# M55M1 register map
File version: 1.0
Registers are 32-bit, read-write, reset 0x0 unless marked. A register's access mark holds for its fields unless they carry their own. Offsets are from the block's base; [hi:lo] are bit positions; {n}, {i} and the like mark numbered series; 'fields as' and 'values as' point back to an identical list.

## SCU_NS — SCU Register Map
Base 0x50402000
0x60 SCU_FNSADDR ro reset not defined — Flash Non-secure Boundary Address Register
  [31:0] FNSADDR — Flash Non-secure Boundary Address. Indicate the base address of Non-secure region set in user configuration. Refer to FMC section for more details.
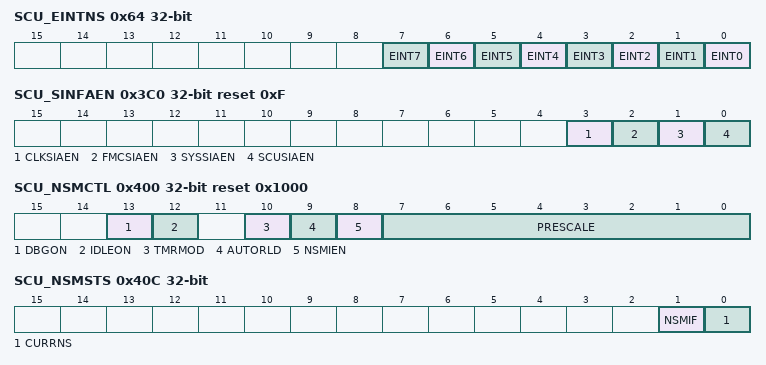
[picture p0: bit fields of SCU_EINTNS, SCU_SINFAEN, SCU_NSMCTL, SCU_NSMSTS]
0x64 SCU_EINTNS — EINT Non-secure Attribution Set Register
  [n] EINT{n} (n=0..7) — Set EINT{n} to Non-secure State
    0=EINT{n} is a secure module (default); 1=EINT{n} is a non-secure module
0x70 SCU_IONS0 — I/O Non-secure Attribution Set Register0
  [15:0] PA — Set GPIO Port A to Non-secure State. Write 1 to set PA to non-secure state. Each bit configures one pin in GPIO port A.
    0=GPIO port A is secure (default); 1=GPIO port A is non-secure
0x74 SCU_IONS1 — I/O Non-secure Attribution Set Register1
  [15:0] PB — Set GPIO Port B to Non-secure State. Write 1 to set PB to non-secure state. Each bit configures one pin in GPIO port B.
    0=GPIO port B is secure (default); 1=GPIO port B is non-secure
0x78 SCU_IONS2 — I/O Non-secure Attribution Set Register2
  [15:0] PC — Set GPIO Port C to Non-secure State. Write 1 to set PC to non-secure state. Each bit configures one pin in GPIO port C.
    0=GPIO port C is secure (default); 1=GPIO port C is non-secure
0x7C SCU_IONS3 — I/O Non-secure Attribution Set Register3
  [15:0] PD — Set GPIO Port D to Non-secure State. Write 1 to set PD to non-secure state. Each bit configures one pin in GPIO port D.
    0=GPIO port D is secure (default); 1=GPIO port D is non-secure
0x80 SCU_IONS4 — I/O Non-secure Attribution Set Register4
  [15:0] PE — Set GPIO Port E to Non-secure State. Write 1 to set PE to non-secure state. Each bit configures one pin in GPIO port E.
    0=GPIO port E is secure (default); 1=GPIO port E is non-secure
0x84 SCU_IONS5 — I/O Non-secure Attribution Set Register5
  [15:0] PF — Set GPIO Port F to Non-secure State. Write 1 to set PF to non-secure state. Each bit configures one pin in GPIO port F.
    0=GPIO port F is secure (default); 1=GPIO port F is non-secure
0x88 SCU_IONS6 — I/O Non-secure Attribution Set Register6
  [15:0] PG — Set GPIO Port G to Non-secure State. Write 1 to set PG to non-secure state. Each bit configures one pin in GPIO port G.
    0=GPIO port G is secure (default); 1=GPIO port G is non-secure
0x8C SCU_IONS7 — I/O Non-secure Attribution Set Register7
  [15:0] PH — Set GPIO Port H to Non-secure State. Write 1 to set PH to non-secure state. Each bit configures one pin in GPIO port H.
    0=GPIO port H is secure (default); 1=GPIO port H is non-secure
0x90 SCU_IONS8 — I/O Non-secure Attribution Set Register8
  [15:0] PI — Set GPIO Port I to Non-secure State. Write 1 to set PI to non-secure state. Each bit configures one pin in GPIO port I.
    0=GPIO port I is secure (default); 1=GPIO port I is non-secure
0x94 SCU_IONS9 — I/O Non-secure Attribution Set Register9
  [15:0] PJ — Set GPIO Port J to Non-secure State. Write 1 to set PJ to non-secure state. Each bit configures one pin in GPIO port J.
    0=GPIO port J is secure (default); 1=GPIO port J is non-secure
0x3C0 SCU_SINFAEN reset 0xF — Shared Information Access Enable Register
  [3] CLKSIAEN — CLKCTL Shared Information Access Enable Bit
    0=Non-secure CPU access CLKCTL Shared information Disabled; 1=Non-secure CPU access CLKCTL Shared information Enabled
  [2] FMCSIAEN — FMC Shared Information Access Enable Bit
    0=Non-secure CPU access FMC Shared information Disabled; 1=Non-secure CPU access FMC Shared information Enabled
  [1] SYSSIAEN — SYS Shared Information Access Enable Bit
    0=Non-secure CPU access SYS Shared information Disabled; 1=Non-secure CPU access SYS Shared information Enabled
  [0] SCUSIAEN — SCU Shared Information Access Enable Bit
    0=Non-secure CPU access SCU Shared information Disabled; 1=Non-secure CPU access SCU Shared information Enabled
0x400 SCU_NSMCTL reset 0x1000 — Non-secure State Monitor Control Register
  [13] DBGON — Monitor Counter Keep Counting When the Chip Is in Debug Mode Enable Bit
    0=The counter will be halted when the core processor is halted by ICE. (default); 1=The counter will keep counting when the core processor is halted by ICE
  [12] IDLEON — Monitor Counter Keep Counting When the Chip Is in Idle Mode Enable Bit. Note: In monitor mode, the counter is always halted when the core processor is in secure state.
    0=The counter will be halted when the chip is in idle mode; 1=The counter will keep counting when the chip is in idle mode. (default)
  [10] TMRMOD — Non-secure Monitor Mode Enable Bit
    0=Monitor mode. The counter will count down when the core processor is in non-secure state. (default); 1=Free-counting mode. The counter will keep counting no matter the core processor is in secure or non-secure state
  [9] AUTORLD — Auto Reload Non-secure State Monitor Counter When CURRNS Changing to 1
    0=Disable clearing non-secure state monitor counter automatically (default); 1=Enable clearing non-secure state monitor counter automatically when the core processor changes from secure state to non-secure state
  [8] NSMIEN — Non-secure State Monitor Interrupt Enable Bit
    0=Non-secure state monitor interrupt Disabled; 1=Non-secure state monitor interrupt Enabled
  [7:0] PRESCALE — Pre-scale Value of Non-secure State Monitor Counter
    0=Counter Disabled
0x404 SCU_NSMLOAD reset 0xFFFFFF — Non-secure State Monitor Reload Value Register
  [23:0] RELOAD — Reload Value for Non-secure State Monitor Counter. The RELOAD value will be reloaded to the counter whenever the counter counts down to 0.
0x408 SCU_NSMVAL reset 0xFFFFFF — Non-secure State Monitor Counter Value Register
  [23:0] VALUE — Counter Value of Non-secure State Monitor Counter. A write of any value clears the VALUE to 0 and also clears NSMIF.
0x40C SCU_NSMSTS — Non-secure State Monitor Status Register
  [1] NSMIF — Non-secure State Monitor Interrupt Flag. Note: This bit is cleared by writing 1.
    0=Counter does not count down to 0 since the last NSMIF has been cleared; 1=Counter counts down to 0
  [0] CURRNS ro — Current Core Processor Secure/Non-secure State (Read Only). Note: This bit can be used to monitor the current secure/non-secure state of the core processor, even if the non-secure state monitor counter is disabled.
    0=Core processor is in secure state; 1=Core processor is in non-secure state
{0x410+4i} SCU_SRAM{i}MPCLUT0 ro (i=0..2) — Security Attribute of memory blocks controlled by SRAM{i}MPC LUT0
  [31:0] BLKLUT — Block-based gating Look Up Table. Each bit indicates the Security state of a single block. When:
    0=The corresponding block is in the Secure state; 1=The corresponding block is in the Non-secure state
0x420 SCU_SRAM3MPCLUT0 ro — Security Attribute of memory blocks controlled by SRAM3MPC LUT0
  fields as SCU_SRAM0MPCLUT0
0x424 SCU_LPSRAMMPCLUT0 ro — Security Attribute of memory blocks controlled by LPSRAMMPC LUT0
  fields as SCU_SRAM0MPCLUT0
{0x430+4i} SCU_SPIM0MPCLUT{i} ro (i=0..7) — Security Attribute of memory blocks controlled by SPIM0MPC LUT{i}
  fields as SCU_SRAM0MPCLUT0
